# MK70F15 register map
Vendor: Freescale Semiconductor, Inc.; Series: Kinetis_K; File version: 1.6
CPU: CM4 r0p1, little endian, no MPU, FPU, VTOR, 4 interrupt priority bits
Registers are 32-bit, read-write, reset 0x0 unless marked. A register's access mark holds for its fields unless they carry their own. Offsets are from the block's base; [hi:lo] are bit positions; {n}, {i} and the like mark numbered series.

## RNG — Random Number Generator Accelerator
Base 0x400A0000; register names take the prefix RNG_
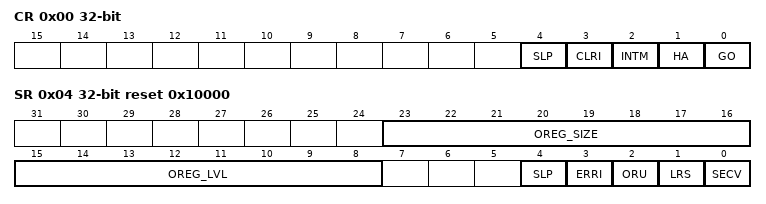
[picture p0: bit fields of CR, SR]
0x00 CR — RNGA Control Register
  [4] SLP — Sleep
    0=RNGA is not in Sleep mode; 1=RNGA is in Sleep mode
  [3] CLRI wo — Clear Interrupt
    0=Do not clear the interrupt; 1=Clear the interrupt
  [2] INTM — Interrupt Mask
    0=Interrupt is enabled; 1=Interrupt is masked
  [1] HA — High Assurance
    0=Notification of security violations is enabled; 1=Notification of security violations is masked
  [0] GO — This bit must be set before the RNGA begins loading data into the RNGA Output Register
    0=RNGA Output Register is not loaded with random data; 1=RNGA Output Register is loaded with random data
0x04 SR ro reset 0x10000 — RNGA Status Register
  [23:16] OREG_SIZE — Output Register Size
  [15:8] OREG_LVL — Output Register Level
  [4] SLP — Sleep
    0=The RNGA is not in Sleep mode; 1=The RNGA is in Sleep mode
  [3] ERRI — Error Interrupt
    0=The RNGA Output Register has not been read while empty; 1=The RNGA Output Register has been read while empty
  [2] ORU — Output Register Underflow
    0=The RNGA Output Register has not been read while empty since last read of the RNGA Status Register; 1=The RNGA Output Register has been read while empty since last read of the RNGA Status Register
  [1] LRS — Last Read Status
    0=Last read was performed while the RNGA Output Register was not empty; 1=Last read was performed while the RNGA Output Register was empty (underflow condition)
  [0] SECV — Security Violation
    0=No security violations have occured or the High Assurance bit (HA) in the RNGA Control Register is not set; 1=A security violation has occurred
0x08 ER wo — RNGA Entropy Register
  [31:0] EXT_ENT — External Entropy
0x0C OR ro — RNGA Output Register
  [31:0] RANDOUT — Random Output

## DAC0 — 12-Bit Digital-to-Analog Converter
Base 0x400CC000; register names take the prefix DAC0_
{0x0+2i} DAT{i}L (i=0..15) 8-bit — DAC Data Low Register
  [7:0] DATA
{0x1+2i} DAT{i}H (i=0..15) 8-bit — DAC Data High Register
  [3:0] DATA
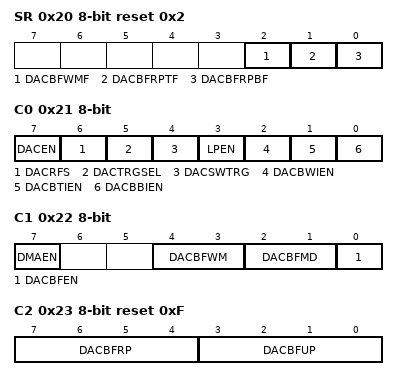
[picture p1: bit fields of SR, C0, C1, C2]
0x20 SR 8-bit reset 0x2 — DAC Status Register
  [2] DACBFWMF — DAC buffer watermark flag
    0=The DAC buffer read pointer has not reached the watermark level; 1=The DAC buffer read pointer has reached the watermark level
  [1] DACBFRPTF — DAC buffer read pointer top position flag
    0=The DAC buffer read pointer is not zero; 1=The DAC buffer read pointer is zero
  [0] DACBFRPBF — DAC buffer read pointer bottom position flag
    0=The DAC buffer read pointer is not equal to the DACBFUP; 1=The DAC buffer read pointer is equal to the DACBFUP
0x21 C0 8-bit — DAC Control Register
  [7] DACEN — DAC enable
    0=The DAC system is disabled; 1=The DAC system is enabled
  [6] DACRFS — DAC Reference Select
    0=The DAC selets DACREF_1 as the reference voltage; 1=The DAC selets DACREF_2 as the reference voltage
  [5] DACTRGSEL — DAC trigger select
    0=The DAC hardware trigger is selected; 1=The DAC software trigger is selected
  [4] DACSWTRG wo — DAC software trigger
    0=The DAC soft trigger is not valid; 1=The DAC soft trigger is valid
  [3] LPEN — DAC low power control
    0=high power mode; 1=low power mode
  [2] DACBWIEN — DAC buffer watermark interrupt enable
    0=The DAC buffer watermark interrupt is disabled; 1=The DAC buffer watermark interrupt is enabled
  [1] DACBTIEN — DAC buffer read pointer top flag interrupt enable
    0=The DAC buffer read pointer top flag interrupt is disabled; 1=The DAC buffer read pointer top flag interrupt is enabled
  [0] DACBBIEN — DAC buffer read pointer bottom flag interrupt enable
    0=The DAC buffer read pointer bottom flag interrupt is disabled; 1=The DAC buffer read pointer bottom flag interrupt is enabled
0x22 C1 8-bit — DAC Control Register 1
  [7] DMAEN — DMA enable select
    0=DMA disabled; 1=DMA enabled. When DMA enabled, DMA request will be generated by original interrupts. And interrupts will not be presented on this module at the same time.
  [4:3] DACBFWM — DAC buffer watermark select
    0=1 word; 1=2 words; 2=3 words; 3=4 words
  [2:1] DACBFMD — DAC buffer work mode select
    0=Normal Mode; 1=Swing Mode; 2=One-Time Scan Mode
  [0] DACBFEN — DAC buffer enable
    0=Buffer read pointer disabled. The converted data is always the first word of the buffer.; 1=Buffer read pointer enabled. The converted data is the word that the read pointer points to. It means converted data can be from any word of the buffer.
0x23 C2 8-bit reset 0xF — DAC Control Register 2
  [7:4] DACBFRP — DAC buffer read pointer
  [3:0] DACBFUP — DAC buffer upper limit

## DAC1 — 12-Bit Digital-to-Analog Converter
Base 0x400CD000; register names take the prefix DAC1_
Registers as DAC0.
